# STM32WBAxx register map
File version: 0.1
Registers are 32-bit, read-write, reset 0x0 unless marked. A register's access mark holds for its fields unless they carry their own. Offsets are from the block's base; [hi:lo] are bit positions; {n}, {i} and the like mark numbered series; 'fields as' and 'values as' point back to an identical list.

## LPGPIO1
Base 0x46020000
Same registers: SEC_LPGPIO1 0x56020000
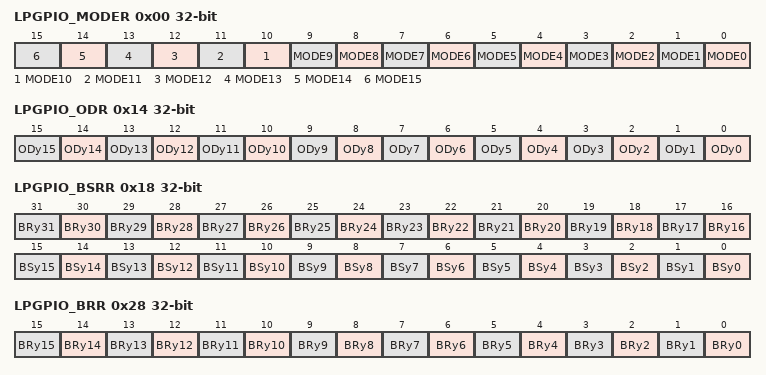
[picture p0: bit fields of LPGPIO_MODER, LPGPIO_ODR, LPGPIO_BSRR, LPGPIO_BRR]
0x00 LPGPIO_MODER — LPGPIO port mode register
  [n] MODE{n} (n=0..15)
0x10 LPGPIO_IDR ro — LPGPIO port input data register
  [15:0] IDy
0x14 LPGPIO_ODR — LPGPIO port output data register
  [n] ODy{n} (n=0..15)
0x18 LPGPIO_BSRR wo — LPGPIO port bit set/reset register
  [n] BRy{n} (n=16..31), [n] BSy{n} (n=0..15)
0x28 LPGPIO_BRR ro — LPGPIO port bit reset register
  [n] BRy{n} (n=0..15)

## OCTOSPIM — OCTOSPI I/O manager
Base 0x420C4000
Same registers: SEC_OCTOSPIM 0x520C4000
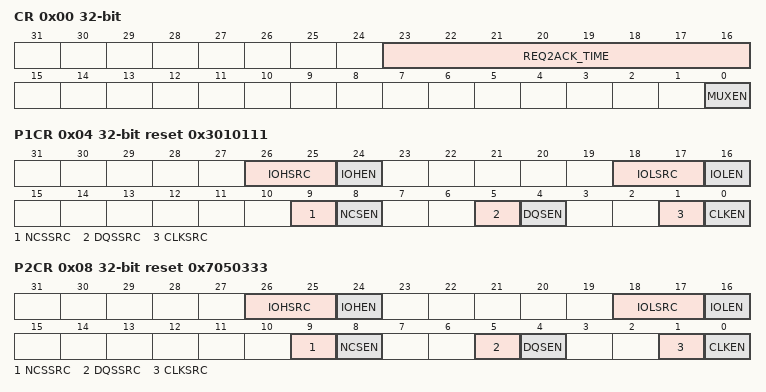
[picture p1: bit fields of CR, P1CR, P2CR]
0x00 CR — control register
  [23:16] REQ2ACK_TIME — REQ to ACK time
  [0] MUXEN — Multiplexed mode enable
0x04 P1CR reset 0x3010111 — OCTOSPI I/O manager Port 1 configuration register
  [26:25] IOHSRC — IOHSR
  [24] IOHEN
  [18:17] IOLSRC
  [16] IOLEN
  [9] NCSSRC
  [8] NCSEN
  [5] DQSSRC
  [4] DQSEN
  [1] CLKSRC
  [0] CLKEN
0x08 P2CR reset 0x7050333 — OCTOSPI I/O manager Port 2 configuration register
  fields as P1CR

## ADC1
Base 0x42028000
Same registers: SEC_ADC1 0x52028000
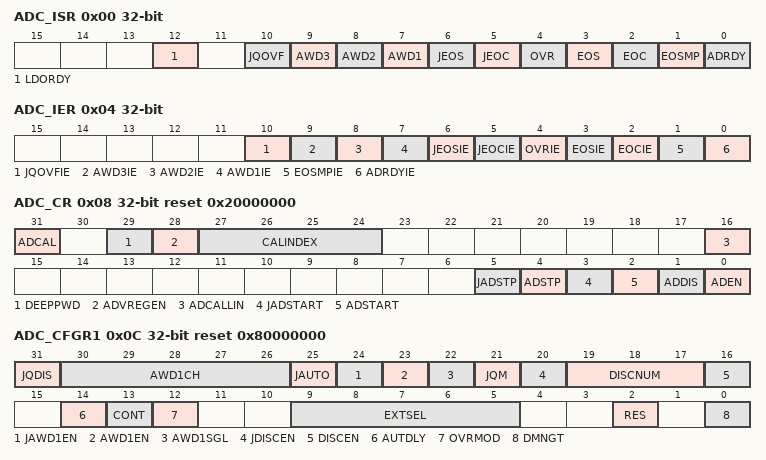
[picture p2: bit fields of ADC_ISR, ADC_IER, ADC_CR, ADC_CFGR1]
0x00 ADC_ISR access per field — ADC interrupt and status register
  [12] LDORDY ro, [10] JQOVF rw, [9] AWD3 rw, [8] AWD2 rw, [7] AWD1 rw, [6] JEOS rw, [5] JEOC rw, [4] OVR rw, [3] EOS rw, [2] EOC rw, [1] EOSMP rw, [0] ADRDY rw
0x04 ADC_IER — ADC interrupt enable register
  [10] JQOVFIE, [9] AWD3IE, [8] AWD2IE, [7] AWD1IE, [6] JEOSIE, [5] JEOCIE, [4] OVRIE, [3] EOSIE, [2] EOCIE, [1] EOSMPIE, [0] ADRDYIE
0x08 ADC_CR access per field reset 0x20000000 — ADC control register
  [31] ADCAL ro, [29] DEEPPWD rw, [28] ADVREGEN rw, [27:24] CALINDEX rw, [16] ADCALLIN rw, [5] JADSTP ro, [4] ADSTP ro, [3] JADSTART ro, [2] ADSTART ro, [1] ADDIS ro, [0] ADEN ro
0x0C ADC_CFGR1 reset 0x80000000 — ADC configuration register
  [31] JQDIS, [30:26] AWD1CH, [25] JAUTO, [24] JAWD1EN, [23] AWD1EN, [22] AWD1SGL, [21] JQM, [20] JDISCEN, [19:17] DISCNUM, [16] DISCEN, [14] AUTDLY, [13] CONT, [12] OVRMOD, [9:5] EXTSEL, [2] RES, [0] DMNGT
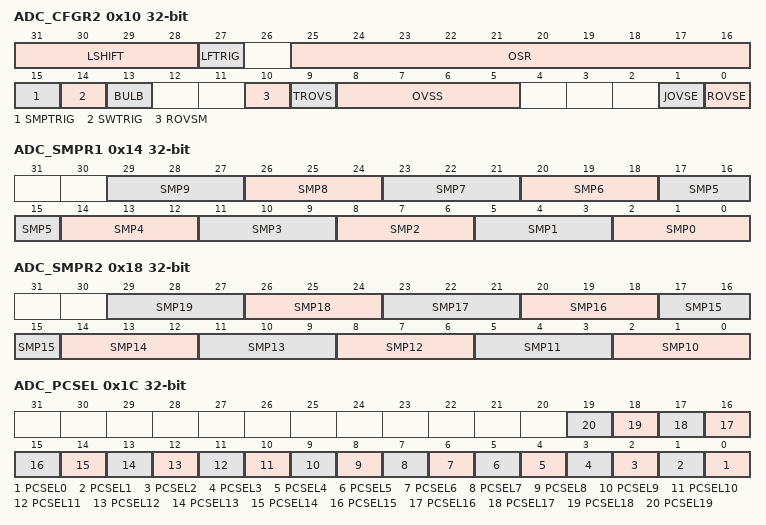
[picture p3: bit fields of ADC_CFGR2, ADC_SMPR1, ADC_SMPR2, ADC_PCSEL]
0x10 ADC_CFGR2 — ADC configuration register 2
  [31:28] LSHIFT, [27] LFTRIG, [25:16] OSR, [15] SMPTRIG, [14] SWTRIG, [13] BULB, [10] ROVSM, [9] TROVS, [8:5] OVSS, [1] JOVSE, [0] ROVSE
0x14 ADC_SMPR1 — ADC sample time register 1
  [3n+2:3n] SMP{n} (n=0..9)
0x18 ADC_SMPR2 — ADC sample time register 2
  [3n-28:3n-30] SMP{n} (n=10..19)
0x1C ADC_PCSEL — ADC channel preselection register
  [n] PCSEL{n} (n=0..19)
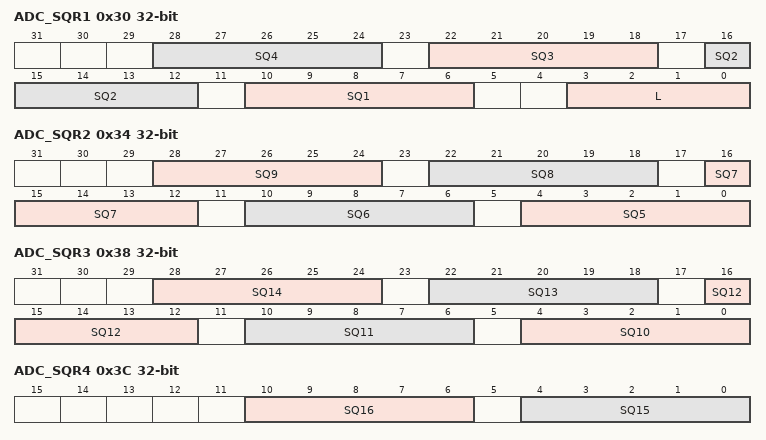
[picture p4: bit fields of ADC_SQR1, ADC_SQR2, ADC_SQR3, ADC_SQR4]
0x30 ADC_SQR1 — ADC regular sequence register 1
  [6n+4:6n] SQ{n} (n=1..4), [3:0] L
0x34 ADC_SQR2 — ADC regular sequence register 2
  [6n-26:6n-30] SQ{n} (n=5..9)
0x38 ADC_SQR3 — ADC regular sequence register 3
  [6n-56:6n-60] SQ{n} (n=10..14)
0x3C ADC_SQR4 — ADC regular sequence register 4
  [10:6] SQ16, [4:0] SQ15
0x40 ADC_DR ro — ADC regular Data Register
  [31:0] RDATA
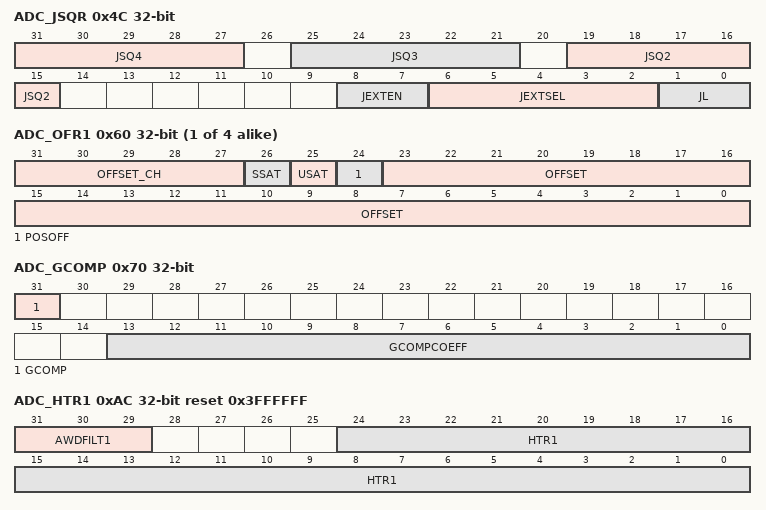
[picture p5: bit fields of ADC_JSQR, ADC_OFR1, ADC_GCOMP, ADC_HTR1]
0x4C ADC_JSQR — ADC injected sequence register
  [31:27] JSQ4, [25:21] JSQ3, [19:15] JSQ2, [8:7] JEXTEN, [6:2] JEXTSEL, [1:0] JL
{0x5C+4i} ADC_OFR{i} (i=1..4) — ADC offset register
  [31:27] OFFSET_CH, [26] SSAT, [25] USAT, [24] POSOFF, [23:0] OFFSET
0x70 ADC_GCOMP — ADC gain compensation register
  [31] GCOMP, [13:0] GCOMPCOEFF
{0x7C+4i} ADC_JDR{i} ro (i=1..4) — ADC injected data register
  [31:0] JDATA
0xA0 ADC_AWD2CR — ADC analog watchdog 2 configuration register
  [19:0] AWD2CH
0xA4 ADC_AWD3CR — ADC analog watchdog 3 configuration register
  [19:0] AWD3CH
0xA8 ADC_LTR1 — ADC watchdog threshold register 1
  [24:0] LTR1
0xAC ADC_HTR1 reset 0x3FFFFFF — ADC watchdog threshold register 1
  [31:29] AWDFILT1, [24:0] HTR1
0xB0 ADC_LTR2 — ADC watchdog lower threshold register 2
  [24:0] LTR2
0xB4 ADC_HTR2 reset 0x3FFFFFF — ADC watchdog higher threshold register 2
  [24:0] HTR2
0xB8 ADC_LTR3 — ADC watchdog lower threshold register 3
  [24:0] LTR3
0xBC ADC_HTR3 reset 0x3FFFFFF — ADC watchdog higher threshold register 3
  [24:0] HTR3
0xC0 ADC_DIFSEL reset 0x3FFFFFF — ADC differential mode selection register
  [19:0] DIFSEL
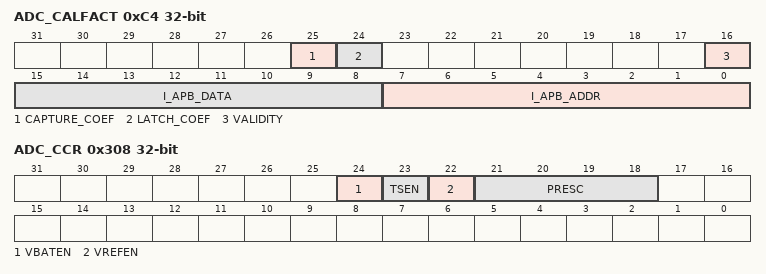
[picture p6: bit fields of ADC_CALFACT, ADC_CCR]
0xC4 ADC_CALFACT access per field — ADC user control register
  [25] CAPTURE_COEF rw, [24] LATCH_COEF rw, [16] VALIDITY ro, [15:8] I_APB_DATA ro, [7:0] I_APB_ADDR ro
0xC8 ADC_CALFACT2 — ADC calibration factor register
  [31:0] CALFACT
0x308 ADC_CCR — ADC calibration factor register
  [24] VBATEN, [23] TSEN, [22] VREFEN, [21:18] PRESC
